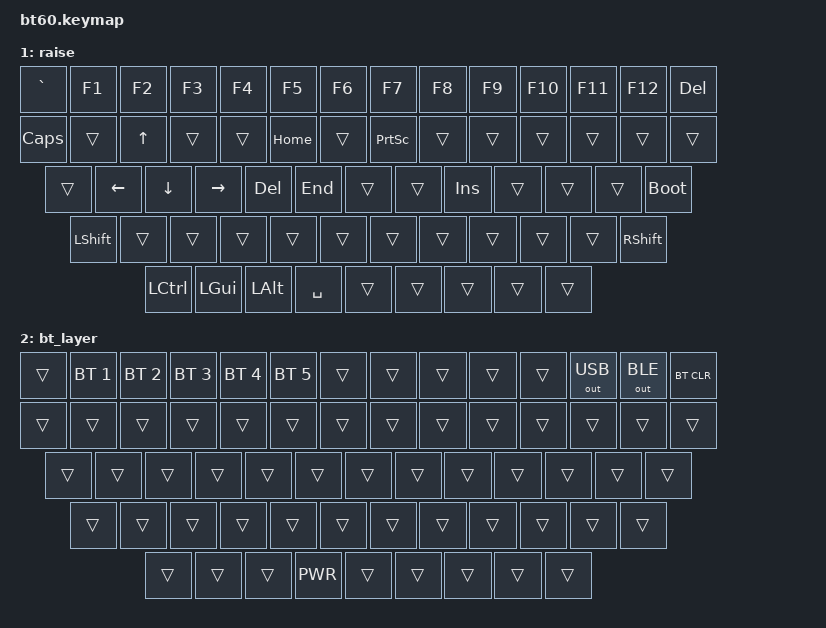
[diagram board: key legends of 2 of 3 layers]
#include <behaviors.dtsi>
#include <dt-bindings/zmk/keys.h>
#include <dt-bindings/zmk/bt.h>
#include <dt-bindings/zmk/outputs.h>

/ {
	keymap {
		compatible = "zmk,keymap";

		default_layer {
				// ------------------------------------------------------------------------------------------
				// | ESC |  1  |  2  |  3  |  4  |  5  |  6  |  7  |  8  |  9  |  0  |  -  |  =  |   BKSP   | DEL
				// | TAB  |  Q  |  W  |  E  |  R  |  T  |  Y  |  U  |  I  |  O  |  P  |  [  |  ]  |   |    |
				// | CAPS  |  A  |  S  |  D  |  F  |  G  |  H  |  J  |  K  |  L  |  ;  |  '  |     ENTER    |
				// |  SHIFT    |  Z  |  X  |  C  |  V  |  B  |  N  |  M  |  ,  |  .  | /   |      SHIFT     |
				// |  CTL  |  WIN  |  ALT  |            SPACE               | ALT | 1    |  MENU    |  CTRL    |
				// ------------------------------------------------------------------------------------------
			bindings = <
				&kp ESC &kp N1 &kp N2 &kp N3 &kp N4 &kp N5 &kp N6 &kp N7 &kp  N8   &kp  N9 &kp  N0  &kp MINUS &kp EQUAL &kp BSPC
				&kp TAB  &kp Q  &kp W  &kp E  &kp R  &kp T  &kp Y  &kp U  &kp  I    &kp  O  &kp  P   &kp LBKT &kp RBKT  &kp BSLH
				&mo 1  &kp A  &kp S  &kp D  &kp F  &kp G  &kp H  &kp J  &kp  K    &kp  L  &kp SEMI &kp SQT           &kp RET
				&kp LSHFT  &kp Z  &kp X  &kp C  &kp V  &kp B  &kp N  &kp M  &kp COMMA &kp DOT &kp FSLH             &kp RSHFT
				&kp LCTRL &kp LGUI &kp LALT            &kp SPACE                          &kp RALT  &mo 2 &kp K_CMENU &kp RCTRL
			>;
			sensor-bindings = <&inc_dec_kp C_VOL_UP C_VOL_DN>;
		};
		raise {
			bindings = <
                &kp GRAVE &kp F1 &kp F2 &kp F3 &kp F4 &kp F5 &kp F6 &kp F7 &kp  F8   &kp  F9 &kp  F10  &kp F11 &kp F12   &kp DEL
                &kp CLCK &trans &kp UP &trans &trans &kp HOME &trans &kp PSCRN &trans &trans &trans &trans &trans &trans
                &trans    &kp LEFT &kp DOWN &kp RIGHT &kp DEL &kp END &trans &trans &kp INS &trans &trans       &trans   &bootloader
                &kp LSHIFT &trans &trans &trans &trans &trans &trans &trans &trans &trans &trans  &kp RSHIFT
                &kp LCTRL &kp LGUI  &kp LALT              &kp SPACE                            &trans   &trans   &trans &trans &trans
			>;
			sensor-bindings = <&inc_dec_kp C_VOL_UP C_VOL_DN>;
		};
        bt_layer {
            bindings = <
		&trans &bt BT_SEL 1 &bt BT_SEL 2 &bt BT_SEL 3 &bt BT_SEL 4 &bt BT_SEL 5 &trans &trans &trans   &trans &trans  &out OUT_USB &out OUT_BLE   &bt BT_CLR
		&trans &trans &trans &trans &trans &trans &trans &trans &trans &trans &trans &trans &trans &trans
		&trans &trans &trans &trans &trans &trans &trans &trans &trans &trans &trans &trans   &trans
                &trans &trans &trans &trans &trans &trans &trans &trans &trans &trans &trans  &trans
                &trans &trans  &trans              &kp K_PWR                            &trans   &trans   &trans &trans &trans
            >;
        };
	};
};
